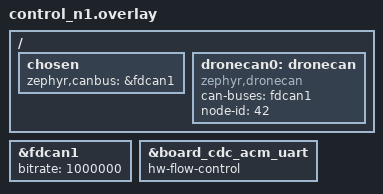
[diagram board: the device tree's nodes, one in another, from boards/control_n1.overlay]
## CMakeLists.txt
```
# SPDX-License-Identifier: Apache-2.0

cmake_minimum_required(VERSION 3.28.0)

# Use the module from this repository so the sample builds standalone.
list(APPEND ZEPHYR_EXTRA_MODULES ${CMAKE_CURRENT_LIST_DIR}/../..)

find_package(Zephyr REQUIRED HINTS $ENV{ZEPHYR_BASE})
project(dronecan_shell_sample)

target_sources(app PRIVATE src/main.c)
```

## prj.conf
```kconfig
CONFIG_CAN=y
CONFIG_LOG=y
CONFIG_SHELL=y
CONFIG_DRONECAN=y
CONFIG_DRONECAN_NODE_TABLE=y
CONFIG_DRONECAN_DNIA_SERVER=y
CONFIG_DRONECAN_DNIA_CLIENT=y
CONFIG_DRONECAN_SHELL=y

# More messages for dc subscribe, dc publish and dc monitor
CONFIG_DRONECAN_MSG_UAVCAN_EQUIPMENT_POWER_BATTERYINFO=y
```

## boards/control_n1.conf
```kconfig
# The shell runs on a USB CDC ACM port, using the USB device next stack, and the
# console is turned off. The board's own console is UART7, which needs a USB-serial adapter.
CONFIG_SERIAL=y
CONFIG_UART_CONSOLE=n
CONFIG_UART_LINE_CTRL=y
CONFIG_USB_DEVICE_STACK_NEXT=y
CONFIG_USBD_CDC_ACM_CLASS=y
CONFIG_CDC_ACM_SERIAL_INITIALIZE_AT_BOOT=y

# The USB stack must not log through the port it is serving
CONFIG_USBD_LOG_LEVEL_OFF=y
CONFIG_USBD_CDC_ACM_LOG_LEVEL_OFF=y

# 3DR USB identifiers (same for all 3DR boards)
CONFIG_CDC_ACM_SERIAL_VID=0x26ac
CONFIG_CDC_ACM_SERIAL_PID=0x1186
CONFIG_CDC_ACM_SERIAL_MANUFACTURER_STRING="3DR"
CONFIG_CDC_ACM_SERIAL_PRODUCT_STRING="Control N1 DroneCAN shell"

CONFIG_MAIN_STACK_SIZE=2048
CONFIG_SHELL_STACK_SIZE=4096
CONFIG_LOG_PROCESS_THREAD_STACK_SIZE=1024
```

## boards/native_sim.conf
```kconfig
CONFIG_DRONECAN_LOOPBACK_MODE=y
```

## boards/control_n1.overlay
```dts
// Shell on a USB CDC ACM port (the board console is UART7)
#include <../boards/common/usb/cdc_acm_serial.dtsi>

/ {
	chosen {
		zephyr,canbus	= &fdcan1;
	};

	dronecan0: dronecan {
		compatible = "zephyr,dronecan";
		can-buses = <&fdcan1>;
		node-id = <42>;
		status = "okay";
	};
};

&fdcan1 {
	bitrate = <1000000>;
};

// The CDC ACM UART discards output while its USB packet is full.
// hw-flow-control makes it wait for a free packet, so no console output is lost.
&board_cdc_acm_uart {
	hw-flow-control;
};
```

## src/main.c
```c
/*
 * Copyright (c) 2026 3DR, Inc.
 * SPDX-License-Identifier: Apache-2.0
 */

#include <zephyr/kernel.h>
#include <zephyr/device.h>
#include <zephyr/logging/log.h>

#include <dronecan.h>

LOG_MODULE_REGISTER(dronecan_shell_sample, LOG_LEVEL_INF);

static const struct device *const dc = DEVICE_DT_GET(DT_NODELABEL(dronecan0));

int main(void)
{
	int ret;

	if (!device_is_ready(dc)) {
		LOG_ERR("%s is not ready", dc->name);
		return -ENODEV;
	}

	ret = dronecan_start(dc);
	if (ret != 0) {
		LOG_ERR("start: %d", ret);
		return ret;
	}
	LOG_INF("node %u started, type 'dc' for the commands", dronecan_get_node_id(dc));

	return 0;
}
```
